# MK61F15WS register map
File version: 1.6
Registers are 32-bit, read-write, reset 0x0 unless marked. A register's access mark holds for its fields unless they carry their own. Offsets are from the block's base; [hi:lo] are bit positions; {n}, {i} and the like mark numbered series.

## SDHC — Secured Digital Host Controller
Base 0x400B1000; register names take the prefix SDHC_
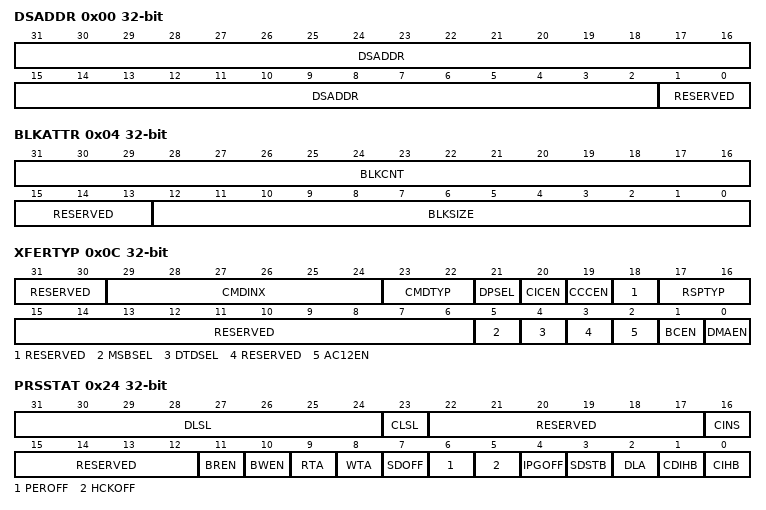
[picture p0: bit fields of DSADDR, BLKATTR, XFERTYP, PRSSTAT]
0x00 DSADDR — DMA System Address Register
  [31:2] DSADDR — DMA System Address
  [1:0] RESERVED ro
0x04 BLKATTR — Block Attributes Register
  [31:16] BLKCNT — Blocks Count For Current Transfer
    0=Stop count; 1=1 block; 2=2 blocks; 0xFFFF=65535 blocks
  [15:13] RESERVED ro
  [12:0] BLKSIZE — Transfer Block Size
    0=No data transfer; 1=1 Byte; 2=2 Bytes; 3=3 Bytes; 4=4 Bytes; 0x1FF=511 Bytes; 0x200=512 Bytes; 0x800=2048 Bytes; 0x1000=4096 Bytes
0x08 CMDARG — Command Argument Register
  [31:0] CMDARG — Command Argument
0x0C XFERTYP — Transfer Type Register
  [31:30] RESERVED ro
  [29:24] CMDINX — Command Index
  [23:22] CMDTYP — Command Type
    0=Normal other commands; 1=Suspend CMD52 for writing bus suspend in CCCR; 2=Resume CMD52 for writing function select in CCCR; 3=Abort CMD12, CMD52 for writing I/O abort in CCCR
  [21] DPSEL — Data Present Select
    0=No data present; 1=Data present
  [20] CICEN — Command Index Check Enable
    0=Disable; 1=Enable
  [19] CCCEN — Command CRC Check Enable
    0=Disable; 1=Enable
  [18] RESERVED ro
  [17:16] RSPTYP — Response Type Select
    0=No response; 1=Response length 136; 2=Response length 48; 3=Response length 48, check busy after response
  [15:6] RESERVED ro
  [5] MSBSEL — Multi/Single Block Select
    0=Single block; 1=Multiple blocks
  [4] DTDSEL — Data Transfer Direction Select
    0=Write (host to card); 1=Read (card to host)
  [3] RESERVED ro
  [2] AC12EN — Auto CMD12 Enable
    0=Disable; 1=Enable
  [1] BCEN — Block Count Enable
    0=Disable; 1=Enable
  [0] DMAEN — DMA Enable
    0=Disable; 1=Enable
{0x10+4i} CMDRSP{i} ro (i=0..3) — Command Response {i}
0x20 DATPORT — Buffer Data Port Register
  [31:0] DATCONT — Data Content
0x24 PRSSTAT ro — Present State Register
  [31:24] DLSL — DAT Line Signal Level
  [23] CLSL — CMD Line Signal Level
  [22:17] RESERVED
  [16] CINS — Card Inserted
    0=Power on reset or no card; 1=Card inserted
  [15:12] RESERVED
  [11] BREN — Buffer Read Enable
    0=Read disable, valid data less than the watermark level exist in the buffer; 1=Read enable, valid data greater than the watermark level exist in the buffer
  [10] BWEN — Buffer Write Enable
    0=Write disable, the buffer can hold valid data less than the write watermark level; 1=Write enable, the buffer can hold valid data greater than the write watermark level
  [9] RTA — Read Transfer Active
    0=No valid data; 1=Transferring data
  [8] WTA — Write Transfer Active
    0=No valid data; 1=Transferring data
  [7] SDOFF — SD Clock Gated Off Internally
    0=SD clock is active; 1=SD clock is gated off
  [6] PEROFF — SDHC clock Gated Off Internally
    0=SDHC clock is active; 1=SDHC clock is gated off
  [5] HCKOFF — System Clock Gated Off Internally
    0=System clock is active; 1=System clock is gated off
  [4] IPGOFF — Bus Clock Gated Off Internally
    0=Bus clock is active; 1=Bus clock is gated off
  [3] SDSTB — SD Clock Stable
    0=Clock is changing frequency and not stable; 1=Clock is stable
  [2] DLA — Data Line Active
    0=DAT line inactive; 1=DAT line active
  [1] CDIHB — Command Inhibit (DAT)
    0=Can issue command which uses the DAT line; 1=Cannot issue command which uses the DAT line
  [0] CIHB — Command Inhibit (CMD)
    0=Can issue command using only CMD line; 1=Cannot issue command
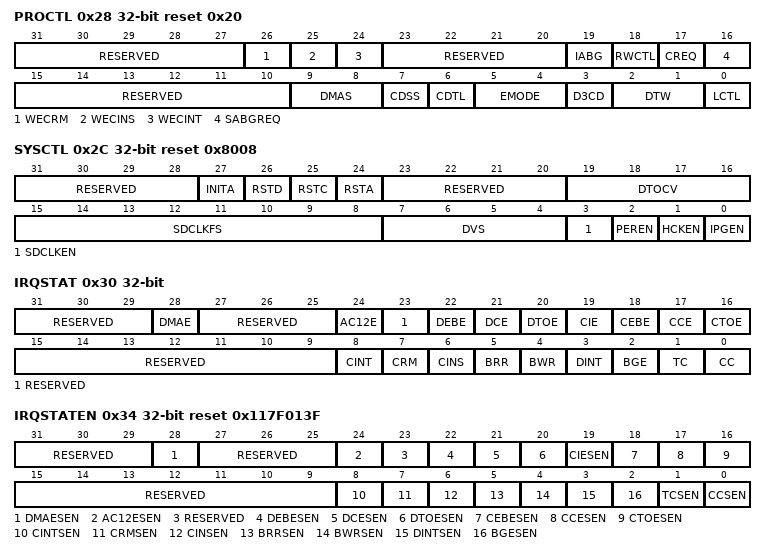
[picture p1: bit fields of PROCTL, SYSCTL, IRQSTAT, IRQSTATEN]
0x28 PROCTL reset 0x20 — Protocol Control Register
  [31:27] RESERVED ro
  [26] WECRM — Wakeup Event Enable On SD Card Removal
    0=Disabled; 1=Enabled
  [25] WECINS — Wakeup Event Enable On SD Card Insertion
    0=Disabled; 1=Enabled
  [24] WECINT — Wakeup Event Enable On Card Interrupt
    0=Disabled; 1=Enabled
  [23:20] RESERVED ro
  [19] IABG — Interrupt At Block Gap
    0=Disabled; 1=Enabled
  [18] RWCTL — Read Wait Control
    0=Disable read wait control, and stop SD clock at block gap when SABGREQ bit is set; 1=Enable read wait control, and assert read wait without stopping SD clock at block gap when SABGREQ bit is set
  [17] CREQ — Continue Request
    0=No effect; 1=Restart
  [16] SABGREQ — Stop At Block Gap Request
    0=Transfer; 1=Stop
  [15:10] RESERVED ro
  [9:8] DMAS — DMA Select
    0=No DMA or simple DMA is selected; 1=ADMA1 is selected; 2=ADMA2 is selected
  [7] CDSS — Card Detect Signal Selection
    0=Card detection level is selected (for normal purpose); 1=Card detection test level is selected (for test purpose)
  [6] CDTL — Card Detect Test Level
    0=Card detect test level is 0, no card inserted; 1=Card detect test level is 1, card inserted
  [5:4] EMODE — Endian Mode
    0=Big endian mode; 1=Half word big endian mode; 2=Little endian mode
  [3] D3CD — DAT3 as Card Detection Pin
    0=DAT3 does not monitor card Insertion; 1=DAT3 as card detection pin
  [2:1] DTW — Data Transfer Width
    0=1-bit mode; 1=4-bit mode; 2=8-bit mode
  [0] LCTL — LED Control
    0=LED off; 1=LED on
0x2C SYSCTL reset 0x8008 — System Control Register
  [31:28] RESERVED ro
  [27] INITA — Initialization Active
  [26] RSTD wo — Software Reset For DAT Line
    0=No reset; 1=Reset
  [25] RSTC wo — Software Reset For CMD Line
    0=No reset; 1=Reset
  [24] RSTA wo — Software Reset For ALL
    0=No reset; 1=Reset
  [23:20] RESERVED ro
  [19:16] DTOCV — Data Timeout Counter Value
    0=SDCLK x 213; 1=SDCLK x 214; 14=SDCLK x 227
  [15:8] SDCLKFS — SDCLK Frequency Select
    1=Base clock divided by 2; 2=Base clock divided by 4; 4=Base clock divided by 8; 8=Base clock divided by 16; 16=Base clock divided by 32; 32=Base clock divided by 64; 64=Base clock divided by 128; 128=Base clock divided by 256
  [7:4] DVS — Divisor
    0=Divisor by 1; 1=Divisor by 2; 14=Divisor by 15; 15=Divisor by 16
  [3] SDCLKEN — SD Clock Enable
  [2] PEREN — Peripheral Clock Enable
    0=SDHC clock will be internally gated off; 1=SDHC clock will not be automatically gated off
  [1] HCKEN — System Clock Enable
    0=System clock will be internally gated off; 1=System clock will not be automatically gated off
  [0] IPGEN — IPG Clock Enable
    0=Bus clock will be internally gated off; 1=Bus clock will not be automatically gated off
0x30 IRQSTAT — Interrupt Status Register
  [31:29] RESERVED ro
  [28] DMAE — DMA Error
    0=No Error; 1=Error
  [27:25] RESERVED ro
  [24] AC12E — Auto CMD12 Error
    0=No Error; 1=Error
  [23] RESERVED ro
  [22] DEBE — Data End Bit Error
    0=No Error; 1=Error
  [21] DCE — Data CRC Error
    0=No Error; 1=Error
  [20] DTOE — Data Timeout Error
    0=No Error; 1=Time out
  [19] CIE — Command Index Error
    0=No Error; 1=Error
  [18] CEBE — Command End Bit Error
    0=No Error; 1=End Bit Error Generated
  [17] CCE — Command CRC Error
    0=No Error; 1=CRC Error Generated
  [16] CTOE — Command Timeout Error
    0=No Error; 1=Time out
  [15:9] RESERVED ro
  [8] CINT — Card Interrupt
    0=No Card Interrupt; 1=Generate Card Interrupt
  [7] CRM — Card Removal
    0=Card state unstable or inserted; 1=Card removed
  [6] CINS — Card Insertion
    0=Card state unstable or removed; 1=Card inserted
  [5] BRR — Buffer Read Ready
    0=Not ready to read buffer; 1=Ready to read buffer
  [4] BWR — Buffer Write Ready
    0=Not ready to write buffer; 1=Ready to write buffer
  [3] DINT — DMA Interrupt
    0=No DMA Interrupt; 1=DMA Interrupt is generated
  [2] BGE — Block Gap Event
    0=No block gap event; 1=Transaction stopped at block gap
  [1] TC — Transfer Complete
    0=Transfer not complete; 1=Transfer complete
  [0] CC — Command Complete
    0=Command not complete; 1=Command complete
0x34 IRQSTATEN reset 0x117F013F — Interrupt Status Enable Register
  [31:29] RESERVED ro
  [28] DMAESEN — DMA Error Status Enable
    0=Masked; 1=Enabled
  [27:25] RESERVED ro
  [24] AC12ESEN — Auto CMD12 Error Status Enable
    0=Masked; 1=Enabled
  [23] RESERVED ro
  [22] DEBESEN — Data End Bit Error Status Enable
    0=Masked; 1=Enabled
  [21] DCESEN — Data CRC Error Status Enable
    0=Masked; 1=Enabled
  [20] DTOESEN — Data Timeout Error Status Enable
    0=Masked; 1=Enabled
  [19] CIESEN — Command Index Error Status Enable
    0=Masked; 1=Enabled
  [18] CEBESEN — Command End Bit Error Status Enable
    0=Masked; 1=Enabled
  [17] CCESEN — Command CRC Error Status Enable
    0=Masked; 1=Enabled
  [16] CTOESEN — Command Timeout Error Status Enable
    0=Masked; 1=Enabled
  [15:9] RESERVED ro
  [8] CINTSEN — Card Interrupt Status Enable
    0=Masked; 1=Enabled
  [7] CRMSEN — Card Removal Status Enable
    0=Masked; 1=Enabled
  [6] CINSEN — Card Insertion Status Enable
    0=Masked; 1=Enabled
  [5] BRRSEN — Buffer Read Ready Status Enable
    0=Masked; 1=Enabled
  [4] BWRSEN — Buffer Write Ready Status Enable
    0=Masked; 1=Enabled
  [3] DINTSEN — DMA Interrupt Status Enable
    0=Masked; 1=Enabled
  [2] BGESEN — Block Gap Event Status Enable
    0=Masked; 1=Enabled
  [1] TCSEN — Transfer Complete Status Enable
    0=Masked; 1=Enabled
  [0] CCSEN — Command Complete Status Enable
    0=Masked; 1=Enabled
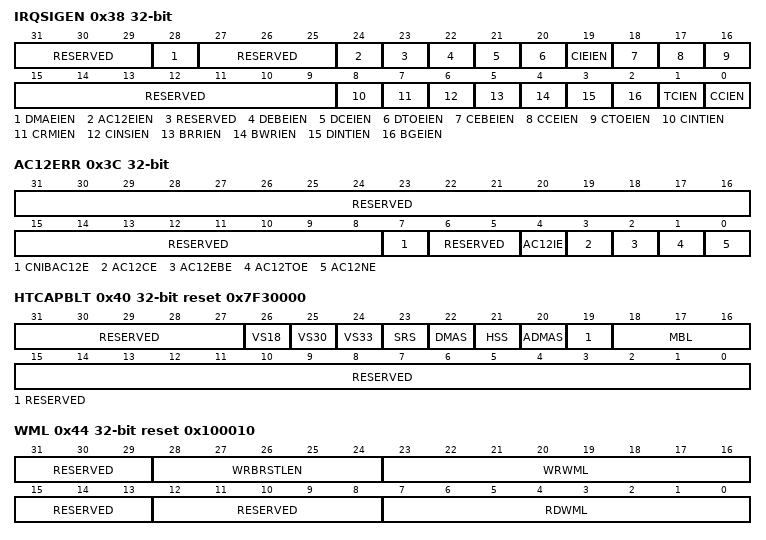
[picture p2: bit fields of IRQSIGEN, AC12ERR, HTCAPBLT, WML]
0x38 IRQSIGEN — Interrupt Signal Enable Register
  [31:29] RESERVED ro
  [28] DMAEIEN — DMA Error Interrupt Enable
    0=Masked; 1=Enabled
  [27:25] RESERVED ro
  [24] AC12EIEN — Auto CMD12 Error Interrupt Enable
    0=Masked; 1=Enabled
  [23] RESERVED ro
  [22] DEBEIEN — Data End Bit Error Interrupt Enable
    0=Masked; 1=Enabled
  [21] DCEIEN — Data CRC Error Interrupt Enable
    0=Masked; 1=Enabled
  [20] DTOEIEN — Data Timeout Error Interrupt Enable
    0=Masked; 1=Enabled
  [19] CIEIEN — Command Index Error Interrupt Enable
    0=Masked; 1=Enabled
  [18] CEBEIEN — Command End Bit Error Interrupt Enable
    0=Masked; 1=Enabled
  [17] CCEIEN — Command CRC Error Interrupt Enable
    0=Masked; 1=Enabled
  [16] CTOEIEN — Command Timeout Error Interrupt Enable
    0=Masked; 1=Enabled
  [15:9] RESERVED ro
  [8] CINTIEN — Card Interrupt Enable
    0=Masked; 1=Enabled
  [7] CRMIEN — Card Removal Interrupt Enable
    0=Masked; 1=Enabled
  [6] CINSIEN — Card Insertion Interrupt Enable
    0=Masked; 1=Enabled
  [5] BRRIEN — Buffer Read Ready Interrupt Enable
    0=Masked; 1=Enabled
  [4] BWRIEN — Buffer Write Ready Interrupt Enable
    0=Masked; 1=Enabled
  [3] DINTIEN — DMA Interrupt Enable
    0=Masked; 1=Enabled
  [2] BGEIEN — Block Gap Event Interrupt Enable
    0=Masked; 1=Enabled
  [1] TCIEN — Transfer Complete Interrupt Enable
    0=Masked; 1=Enabled
  [0] CCIEN — Command Complete Interrupt Enable
    0=Masked; 1=Enabled
0x3C AC12ERR ro — Auto CMD12 Error Status Register
  [31:8] RESERVED
  [7] CNIBAC12E — Command Not Issued By Auto CMD12 Error
    0=No error; 1=Not issued
  [6:5] RESERVED
  [4] AC12IE — Auto CMD12 Index Error
    0=No error; 1=Error, the CMD index in response is not CMD12
  [3] AC12CE — Auto CMD12 CRC Error
    0=No CRC error; 1=CRC Error met in auto CMD12 Response
  [2] AC12EBE — Auto CMD12 End Bit Error
    0=No error; 1=End bit error generated
  [1] AC12TOE — Auto CMD12 Timeout Error
    0=No error; 1=Time out
  [0] AC12NE — Auto CMD12 Not Executed
    0=Executed; 1=Not executed
0x40 HTCAPBLT ro reset 0x7F30000 — Host Controller Capabilities
  [31:27] RESERVED
  [26] VS18 — Voltage Support 1.8 V
    0=1.8 V not supported; 1=1.8 V supported
  [25] VS30 — Voltage Support 3.0 V
    0=3.0 V not supported; 1=3.0 V supported
  [24] VS33 — Voltage Support 3.3 V
    0=3.3 V not supported; 1=3.3 V supported
  [23] SRS — Suspend/Resume Support
    0=Not supported; 1=Supported
  [22] DMAS — DMA Support
    0=DMA not supported; 1=DMA supported
  [21] HSS — High Speed Support
    0=High speed not supported; 1=High speed supported
  [20] ADMAS — ADMA Support
    0=Advanced DMA not supported; 1=Advanced DMA supported
  [19] RESERVED
  [18:16] MBL — Max Block Length
    0=512 bytes; 1=1024 bytes; 2=2048 bytes; 3=4096 bytes
  [15:0] RESERVED
0x44 WML reset 0x100010 — Watermark Level Register
  [31:29] RESERVED ro
  [28:24] WRBRSTLEN ro
  [23:16] WRWML — Write Watermark Level
  [15:13] RESERVED ro
  [12:8] RESERVED ro
  [7:0] RDWML — Read Watermark Level
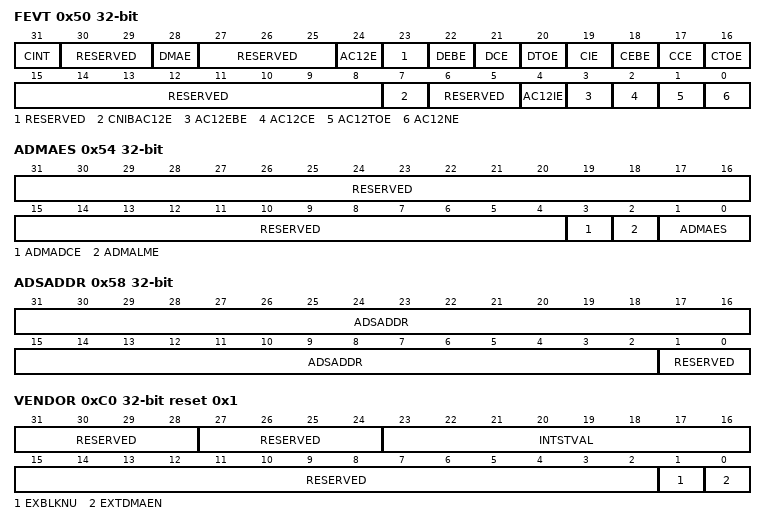
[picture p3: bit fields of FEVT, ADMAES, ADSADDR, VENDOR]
0x50 FEVT wo — Force Event Register
  [31] CINT — Force Event Card Interrupt
  [30:29] RESERVED
  [28] DMAE — Force Event DMA Error
  [27:25] RESERVED
  [24] AC12E — Force Event Auto Command 12 Error
  [23] RESERVED
  [22] DEBE — Force Event Data End Bit Error
  [21] DCE — Force Event Data CRC Error
  [20] DTOE — Force Event Data Time Out Error
  [19] CIE — Force Event Command Index Error
  [18] CEBE — Force Event Command End Bit Error
  [17] CCE — Force Event Command CRC Error
  [16] CTOE — Force Event Command Time Out Error
  [15:8] RESERVED
  [7] CNIBAC12E — Force Event Command Not Executed By Auto Command 12 Error
  [6:5] RESERVED
  [4] AC12IE — Force Event Auto Command 12 Index Error
  [3] AC12EBE — Force Event Auto Command 12 End Bit Error
  [2] AC12CE — Force Event Auto Command 12 CRC Error
  [1] AC12TOE — Force Event Auto Command 12 Time Out Error
  [0] AC12NE — Force Event Auto Command 12 Not Executed
0x54 ADMAES ro — ADMA Error Status Register
  [31:4] RESERVED
  [3] ADMADCE — ADMA Descritor Error
    0=No error; 1=Error
  [2] ADMALME — ADMA Length Mismatch Error
    0=No error; 1=Error
  [1:0] ADMAES — ADMA Error State (when ADMA Error is occurred.)
0x58 ADSADDR — ADMA System Address Register
  [31:2] ADSADDR — ADMA System Address
  [1:0] RESERVED ro
0xC0 VENDOR reset 0x1 — Vendor Specific Register
  [31:28] RESERVED ro
  [27:24] RESERVED ro
  [23:16] INTSTVAL ro — Internal State Value
  [15:2] RESERVED ro
  [1] EXBLKNU — Exact block number block read enable for SDIO CMD53
    0=none exact block read; 1=Exact block read for SDIO CMD53
  [0] EXTDMAEN — External DMA Request Enable
    0=In any scenario, SDHC does not send out external DMA request; 1=When internal DMA is not active, the external DMA request will be sent out
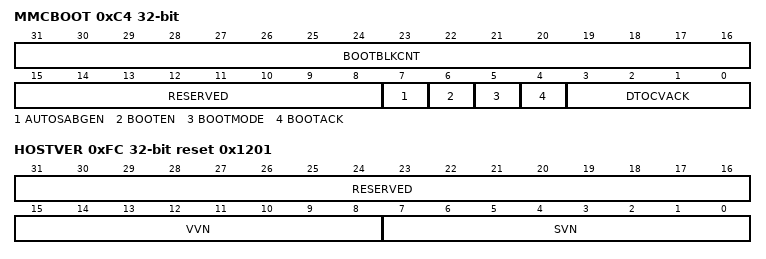
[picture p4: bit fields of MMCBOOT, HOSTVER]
0xC4 MMCBOOT
  [31:16] BOOTBLKCNT
  [15:8] RESERVED ro
  [7] AUTOSABGEN
  [6] BOOTEN — Boot mode enable
    0=Fast boot disable; 1=Fast boot enable
  [5] BOOTMODE — Boot mode select
    0=Normal boot; 1=Alternative boot
  [4] BOOTACK — Boot ack mode select
    0=No ack; 1=Ack
  [3:0] DTOCVACK — Boot ACK time out counter value.
    {v}=SDCLK x 2^{v+8} (v=0..7); 14=SDCLK x 2^22
0xFC HOSTVER ro reset 0x1201 — Host Controller Version
  [31:16] RESERVED
  [15:8] VVN — Vendor Version Number
    0=Freescale SDHC version 1.0; 16=Freescale SDHC version 2.0; 17=Freescale SDHC version 2.1; 18=Freescale SDHC version 2.2
  [7:0] SVN — Specification Version Number
    1=SD host specification version 2.0, supports test event register and ADMA
